AUTOSAR XML (schema 4-2-1)
package /RootP_ASWC_A27
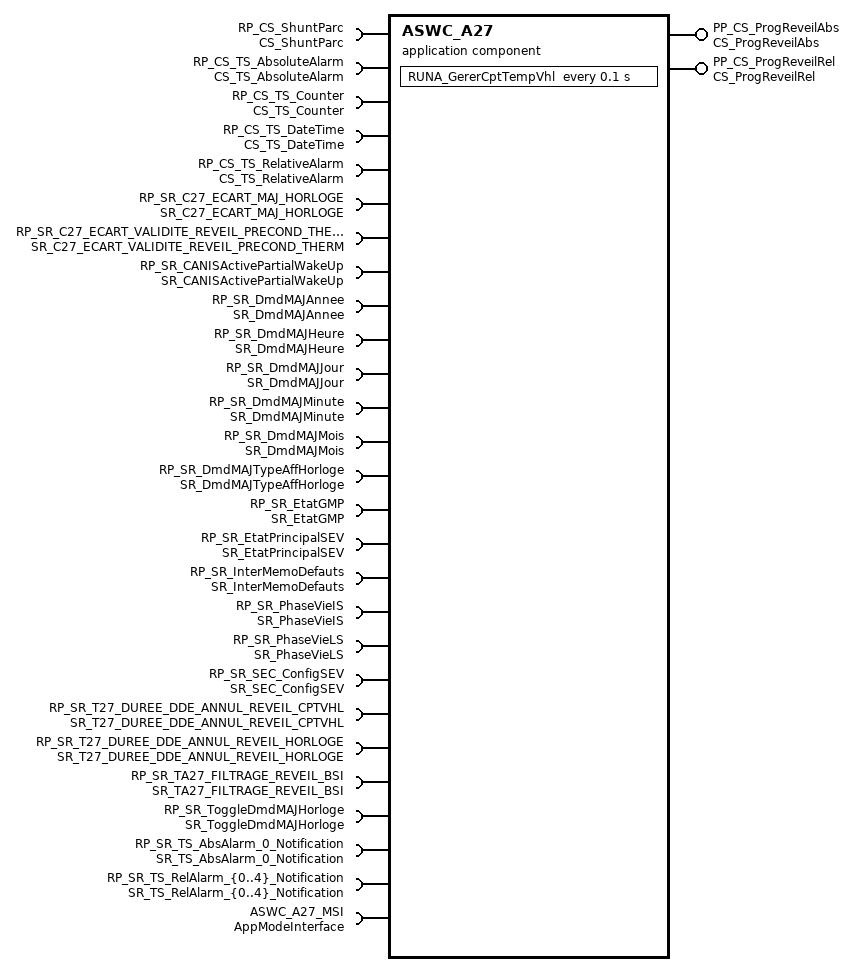
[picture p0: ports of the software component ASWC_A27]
  application sw component type ASWC_A27
    provide port PP_CS_ProgReveilAbs: provided-com-specs=[{operation=Release, queue-length=1}, {operation=Request, queue-length=1}], provided-interface=CS_ProgReveilAbs
    provide port PP_CS_ProgReveilRel: provided-com-specs=[{operation=Release, queue-length=1}, {operation=Request, queue-length=1}], provided-interface=CS_ProgReveilRel
    29 x provide/require port:
      PRP_SR_Annee: nonqueued-receiver-com-spec{data-element=Annee, enable-update=0, handle-data-status=1, handle-never-received=0, init-value=CONST_t_cAnnee_0x84E:2126}, provided-required-interface=SR_Annee
      PRP_SR_AnneePourAff: nonqueued-receiver-com-spec{data-element=AnneePourAff, enable-update=0, handle-data-status=1, handle-never-received=0, init-value=CONST_AnneePourAff_t_cAnneeAff_cAnneeAff_Indisponible:126}, provided-required-interface=SR_AnneePourAff
      PRP_SR_CptTempVehicule: nonqueued-receiver-com-spec{data-element=CptTempVehicule, enable-update=0, handle-data-status=1, handle-never-received=0, init-value=CONST_tDWORD_0xFFFFFFFE:4294967294}, provided-required-interface=SR_CptTempVehicule
      PRP_SR_DatationDefaut: nonqueued-receiver-com-spec{data-element=DatationDefaut, enable-update=0, handle-data-status=1, handle-never-received=0, init-value=CONST_tDWORD_0:0}, provided-required-interface=SR_DatationDefaut
      PRP_SR_Heure: nonqueued-receiver-com-spec{data-element=Heure, enable-update=0, handle-data-status=1, handle-never-received=0, init-value=CONST_Heure_t_cHeure_cHeure_Indisponible:30}, provided-required-interface=SR_Heure
      PRP_SR_HeureCAN: nonqueued-receiver-com-spec{data-element=HeureCAN, enable-update=0, handle-data-status=1, handle-never-received=0, init-value=CONST_HeureCAN_t_cHeure_cHeure_Indisponible:30}, provided-required-interface=SR_HeureCAN
      PRP_SR_Jour: nonqueued-receiver-com-spec{data-element=Jour, enable-update=0, handle-data-status=1, handle-never-received=0, init-value=CONST_t_cJour_0x3E:62}, provided-required-interface=SR_Jour
      PRP_SR_JourSemaine: nonqueued-receiver-com-spec{data-element=JourSemaine, enable-update=0, handle-data-status=1, handle-never-received=0, init-value=CONST_JourSemaine_t_cJourSemaine_cJourSemaine_Indisponible:14}, provided-required-interface=SR_JourSemaine
      PRP_SR_Minute: nonqueued-receiver-com-spec{data-element=Minute, enable-update=0, handle-data-status=1, handle-never-received=0, init-value=CONST_Minute_t_cMinute_cMinute_Indisponible:62}, provided-required-interface=SR_Minute
      PRP_SR_MinuteCAN: nonqueued-receiver-com-spec{data-element=MinuteCAN, enable-update=0, handle-data-status=1, handle-never-received=0, init-value=CONST_MinuteCAN_t_cMinute_cMinute_Indisponible:62}, provided-required-interface=SR_MinuteCAN
      PRP_SR_Mois: nonqueued-receiver-com-spec{data-element=Mois, enable-update=0, handle-data-status=1, handle-never-received=0, init-value=CONST_Mois_t_cMois_cMois_Indisponible:14}, provided-required-interface=SR_Mois
      PRP_SR_SEC_Affichage: nonqueued-receiver-com-spec{data-element=SEC_Affichage, enable-update=0, handle-data-status=1, handle-never-received=0, init-value=CONST_tLOG_1:1}, provided-required-interface=SR_SEC_Affichage
      PRP_SR_SEC_CptRAZGCT: nonqueued-receiver-com-spec{data-element=SEC_CptRAZGCT, enable-update=0, handle-data-status=1, handle-never-received=0, init-value=CONST_SEC_CptRAZGCT_t_cCptRAZ_cCptRAZ_Indisponible:254}, provided-required-interface=SR_SEC_CptRAZGCT
      PRP_SR_SEC_EtatProgRevGEEAQEB: nonqueued-receiver-com-spec{data-element=SEC_EtatProgRevGEEAQEB, enable-update=0, handle-data-status=1, handle-never-received=0, init-value=CONST_SEC_EtatProgRevGEEAQEB_t_cEtatProgRev_cEtatProgRev_ReveilNonProg:60}, provided-required-interface=SR_SEC_EtatProgRevGEEAQEB
      PRP_SR_SEC_EtatProgRevGEEDCM: nonqueued-receiver-com-spec{data-element=SEC_EtatProgRevGEEDCM, enable-update=0, handle-data-status=1, handle-never-received=0, init-value=CONST_SEC_EtatProgRevGEEDCM_t_cEtatProgRev_cEtatProgRev_ReveilNonProg:60}, provided-required-interface=SR_SEC_EtatProgRevGEEDCM
      PRP_SR_SEC_EtatProgRevPrecond: nonqueued-receiver-com-spec{data-element=SEC_EtatProgRevPrecond, enable-update=0, handle-data-status=1, handle-never-received=0, init-value=CONST_t_cEtatProgRev_0x96:150}, provided-required-interface=SR_SEC_EtatProgRevPrecond
      PRP_SR_SEC_EtatProgRevPrecondElec: nonqueued-receiver-com-spec{data-element=SEC_EtatProgRevPrecondElec, enable-update=0, handle-data-status=1, handle-never-received=0, init-value=CONST_tFLOAT_0x96:150}, provided-required-interface=SR_SEC_EtatProgRevPrecondElec
      PRP_SR_SEC_EtatProgRevPrecondTherm: nonqueued-receiver-com-spec{data-element=SEC_EtatProgRevPrecondTherm, enable-update=0, handle-data-status=1, handle-never-received=0, init-value=CONST_t_cEtatProgRev_0x96:150}, provided-required-interface=SR_SEC_EtatProgRevPrecondTherm
      PRP_SR_SEC_EtatProgRevRTAB: nonqueued-receiver-com-spec{data-element=SEC_EtatProgRevRTAB, enable-update=0, handle-data-status=1, handle-never-received=0, init-value=CONST_SEC_EtatProgRevRTAB_t_cEtatProgRev_cEtatProgRev_ReveilNonProg:60}, provided-required-interface=SR_SEC_EtatProgRevRTAB
      PRP_SR_SEC_HProgRevPrecondTherm: nonqueued-receiver-com-spec{data-element=SEC_HProgRevPrecondTherm, enable-update=0, handle-data-status=1, handle-never-received=0, init-value=CONST_SEC_HProgRevPrecondTherm_t_cHProgPrecondTherm_cHProgPrecondTherm_Aucun:65534}, provided-required-interface=SR_SEC_HProgRevPrecondTherm
      PRP_SR_SEC_TypeAffichageHorloge: nonqueued-receiver-com-spec{data-element=SEC_TypeAffichageHorloge, enable-update=0, handle-data-status=1, handle-never-received=0, init-value=CONST_SEC_TypeAffichageHorloge_t_cTypeAffichHor_cTypeAffichHor_24H:1}, provided-required-interface=SR_SEC_TypeAffichageHorloge
      PRP_SR_ToggleEnvCptTempVhl: nonqueued-receiver-com-spec{data-element=ToggleEnvCptTempVhl, enable-update=0, handle-data-status=1, handle-never-received=0, init-value=CONST_tLOG_0:0}, provided-required-interface=SR_ToggleEnvCptTempVhl
      PRP_SR_ToggleMAJDateHeure: nonqueued-receiver-com-spec{data-element=ToggleMAJDateHeure, enable-update=0, handle-data-status=1, handle-never-received=0, init-value=CONST_tLOG_0:0}, provided-required-interface=SR_ToggleMAJDateHeure
      PRP_SR_WSParTimerGEEAQEB: nonqueued-receiver-com-spec{data-element=WSParTimerGEEAQEB, enable-update=0, handle-data-status=1, handle-never-received=0, init-value=CONST_tLOG_0:0}, provided-required-interface=SR_WSParTimerGEEAQEB
      PRP_SR_WSParTimerGEEDCM: nonqueued-receiver-com-spec{data-element=WSParTimerGEEDCM, enable-update=0, handle-data-status=1, handle-never-received=0, init-value=CONST_tLOG_0:0}, provided-required-interface=SR_WSParTimerGEEDCM
      PRP_SR_WSParTimerPrecElec: nonqueued-receiver-com-spec{data-element=WSParTimerPrecElec, enable-update=0, handle-data-status=1, handle-never-received=0, init-value=CONST_tLOG_0:0}, provided-required-interface=SR_WSParTimerPrecElec
      PRP_SR_WSParTimerPrecond: nonqueued-receiver-com-spec{data-element=WSParTimerPrecond, enable-update=0, handle-data-status=1, handle-never-received=0, init-value=CONST_tLOG_0:0}, provided-required-interface=SR_WSParTimerPrecond
      PRP_SR_WSParTimerPrecTherm: nonqueued-receiver-com-spec{data-element=WSParTimerPrecTherm, enable-update=0, handle-data-status=1, handle-never-received=0, init-value=CONST_tLOG_0:0}, provided-required-interface=SR_WSParTimerPrecTherm
      PRP_SR_WSParTimerRTAB: nonqueued-receiver-com-spec{data-element=WSParTimerRTAB, enable-update=0, handle-data-status=1, handle-never-received=0, init-value=CONST_tLOG_0:0}, provided-required-interface=SR_WSParTimerRTAB
    31 x require port:
      RP_CS_ShuntParc: required-interface=CS_ShuntParc
      RP_CS_TS_AbsoluteAlarm: required-interface=CS_TS_AbsoluteAlarm
      RP_CS_TS_Counter: required-interface=CS_TS_Counter
      RP_CS_TS_DateTime: required-interface=CS_TS_DateTime
      RP_CS_TS_RelativeAlarm: required-interface=CS_TS_RelativeAlarm
      RP_SR_C27_ECART_MAJ_HORLOGE: nonqueued-receiver-com-spec{data-element=C27_ECART_MAJ_HORLOGE, enable-update=0, handle-data-status=1, handle-never-received=0, init-value=CONST_t_C27_ECART_MAJ_HORLOGE_60:60}, required-interface=SR_C27_ECART_MAJ_HORLOGE
      RP_SR_C27_ECART_VALIDITE_REVEIL_PRECOND_THERM: nonqueued-receiver-com-spec{data-element=C27_ECART_VALIDITE_REVEIL_PRECOND_THERM, enable-update=0, handle-data-status=1, handle-never-received=0, init-value=CONST_tBYTE_60:60}, required-interface=SR_C27_ECART_VALIDITE_REVEIL_PRECOND_THERM
      RP_SR_CANISActivePartialWakeUp: nonqueued-receiver-com-spec{data-element=CANISActivePartialWakeUp, enable-update=0, handle-data-status=1, handle-never-received=0, init-value=CONST_t_cCANISPartialWakeUp_0:0}, required-interface=SR_CANISActivePartialWakeUp
      RP_SR_DmdMAJAnnee: nonqueued-receiver-com-spec{data-element=DmdMAJAnnee, enable-update=0, handle-data-status=1, handle-never-received=0, init-value=CONST_DmdMAJAnnee_t_cAnnee_cAnnee_Indisponible:2126}, required-interface=SR_DmdMAJAnnee
      RP_SR_DmdMAJHeure: nonqueued-receiver-com-spec{data-element=DmdMAJHeure, enable-update=0, handle-data-status=1, handle-never-received=0, init-value=CONST_DmdMAJHeure_t_cHeure_cHeure_Indisponible:30}, required-interface=SR_DmdMAJHeure
      RP_SR_DmdMAJJour: nonqueued-receiver-com-spec{data-element=DmdMAJJour, enable-update=0, handle-data-status=1, handle-never-received=0, init-value=CONST_DmdMAJJour_t_cJour_cJour_Indisponible:62}, required-interface=SR_DmdMAJJour
      RP_SR_DmdMAJMinute: nonqueued-receiver-com-spec{data-element=DmdMAJMinute, enable-update=0, handle-data-status=1, handle-never-received=0, init-value=CONST_DmdMAJMinute_t_cMinute_cMinute_Indisponible:62}, required-interface=SR_DmdMAJMinute
      RP_SR_DmdMAJMois: nonqueued-receiver-com-spec{data-element=DmdMAJMois, enable-update=0, handle-data-status=1, handle-never-received=0, init-value=CONST_DmdMAJMois_t_cMois_cMois_Indisponible:14}, required-interface=SR_DmdMAJMois
      RP_SR_DmdMAJTypeAffHorloge: nonqueued-receiver-com-spec{data-element=DmdMAJTypeAffHorloge, enable-update=0, handle-data-status=1, handle-never-received=0, init-value=CONST_DmdMAJTypeAffHorloge_t_cTypeAffichHor_cTypeAffichHor_24H:1}, required-interface=SR_DmdMAJTypeAffHorloge
      RP_SR_EtatGMP: nonqueued-receiver-com-spec{data-element=EtatGMP, enable-update=0, handle-data-status=1, handle-never-received=0, init-value=CONST_t_GM_GMP_1:1}, required-interface=SR_EtatGMP
      RP_SR_EtatPrincipalSEV: nonqueued-receiver-com-spec{data-element=EtatPrincipalSEV, enable-update=0, handle-data-status=1, handle-never-received=0, init-value=CONST_t_SEV_0x69:105}, required-interface=SR_EtatPrincipalSEV
      RP_SR_InterMemoDefauts: nonqueued-receiver-com-spec{data-element=InterMemoDefauts, enable-update=0, handle-data-status=1, handle-never-received=0, init-value=CONST_tLOG_0:0}, required-interface=SR_InterMemoDefauts
      RP_SR_PhaseVieIS: nonqueued-receiver-com-spec{data-element=PhaseVieIS, enable-update=0, handle-data-status=1, handle-never-received=0, init-value=CONST_PhaseVieIS_t_cCANIS_cCANIS_OFF:0}, required-interface=SR_PhaseVieIS
      RP_SR_PhaseVieLS: nonqueued-receiver-com-spec{data-element=PhaseVieLS, enable-update=0, handle-data-status=1, handle-never-received=0, init-value=CONST_t_cCANLS_0:0}, required-interface=SR_PhaseVieLS
      RP_SR_SEC_ConfigSEV: nonqueued-receiver-com-spec{data-element=SEC_ConfigSEV, enable-update=0, handle-data-status=1, handle-never-received=0, init-value=CONST_t_cCSEV_4:4}, required-interface=SR_SEC_ConfigSEV
      RP_SR_T27_DUREE_DDE_ANNUL_REVEIL_CPTVHL: nonqueued-receiver-com-spec{data-element=T27_DUREE_DDE_ANNUL_REVEIL_CPTVHL, enable-update=0, handle-data-status=1, handle-never-received=0, init-value=CONST_tBYTE_20:20}, required-interface=SR_T27_DUREE_DDE_ANNUL_REVEIL_CPTVHL
      RP_SR_T27_DUREE_DDE_ANNUL_REVEIL_HORLOGE: nonqueued-receiver-com-spec{data-element=T27_DUREE_DDE_ANNUL_REVEIL_HORLOGE, enable-update=0, handle-data-status=1, handle-never-received=0, init-value=CONST_tBYTE_20:20}, required-interface=SR_T27_DUREE_DDE_ANNUL_REVEIL_HORLOGE
      RP_SR_TA27_FILTRAGE_REVEIL_BSI: nonqueued-receiver-com-spec{data-element=TA27_FILTRAGE_REVEIL_BSI, enable-update=0, handle-data-status=1, handle-never-received=0, init-value=CONST_tBYTE_2:2}, required-interface=SR_TA27_FILTRAGE_REVEIL_BSI
      RP_SR_ToggleDmdMAJHorloge: nonqueued-receiver-com-spec{data-element=ToggleDmdMAJHorloge, enable-update=0, handle-data-status=1, handle-never-received=0, init-value=CONST_tLOG_0:0}, required-interface=SR_ToggleDmdMAJHorloge
      RP_SR_TS_AbsAlarm_0_Notification: nonqueued-receiver-com-spec{data-element=AbsAlarm_0_State, enable-update=0, handle-data-status=1, handle-never-received=0, init-value=CONST_t_cAlarm_0:0}, required-interface=SR_TS_AbsAlarm_0_Notification
      RP_SR_TS_RelAlarm_{0..4}_Notification: nonqueued-receiver-com-spec{data-element=RelAlarm_{0..4}_State, enable-update=0, handle-data-status=1, handle-never-received=0, init-value=CONST_t_cAlarm_0:0}, required-interface=SR_TS_RelAlarm_{0..4}_Notification
      ASWC_A27_MSI: required-interface=AppModeInterface
    behavior IB_ASWC_A27: data-type-mapping=ApplicationModeMapping, handle-termination-and-restart=NO-SUPPORT
      ar-typed-per-instance-memorys:
        45 x data:
          PA27_AnneePrec: type=t_cAnnee, init-value=CONST_PA27_AnneePrec_t_cAnnee_cAnnee_Indisponible:2126
          PA27_CoherenceDate_NOK: type=tLOG, init-value=CONST_tLOG_0:0
          PA27_ConditionsMAJDateHeureOK: type=tLOG, init-value=CONST_tLOG_0:0
          PA27_ConditionsRtMAJCptTempVhlOK: type=tLOG, init-value=CONST_tLOG_0:0
          PA27_CptTempoAppa_ABS_SAVE_CPT_TEMPOREL: type=tWORD, init-value=CONST_tWORD_0:0
          PA27_CptTempoAppa_HorlogeInvalide: type=tWORD, init-value=CONST_tWORD_0:0
          PA27_CptTempoDisp_ABS_SAVE_CPT_TEMPOREL: type=tWORD, init-value=CONST_tWORD_0:0
          PA27_CptTempoDisp_HorlogeInvalide: type=tWORD, init-value=CONST_tWORD_0:0
          PA27_DateTimeInv: type=tLOG, init-value=CONST_tLOG_0:0
          PA27_DbrtBATT_Prec: type=tLOG, init-value=CONST_tLOG_0:0
          PA27_DefautPrec_ABS_SAVE_CPT_TEMPOREL: type=tBYTE, init-value=CONST_tBYTE_0:0
          PA27_DefautPrec_HorlogeInvalide: type=tBYTE, init-value=CONST_tBYTE_0:0
          PA27_EntreesRtMAJDateHeureOK: type=tLOG, init-value=CONST_tLOG_0:0
          PA27_EnvCptTempVhl: type=tLOG, init-value=CONST_tLOG_0:0
          PA27_Flag_DEF_ABS_SAVE_CPT_TEMPOREL: type=tLOG, init-value=CONST_tLOG_0:0
          PA27_FlagDeRtDde_MAJDateHeure: type=tBinaire, init-value=CONST_PA27_FlagDeRtDde_MAJDateHeure_tBinaire_cFaux:0
          PA27_FlagDeRtMAJCptTempVhlOK: type=tBinaire, init-value=CONST_PA27_FlagDeRtMAJCptTempVhlOK_tBinaire_cFaux:0
          PA27_HeurePrec: type=t_cHeure, init-value=CONST_PA27_HeurePrec_t_cHeure_cHeure_Indisponible:30
          PA27_HeurePREC: type=t_cHeure, init-value=CONST_PA27_HeurePREC_t_cHeure_cHeure_Indisponible:30
          PA27_InvPrecTimeEnMinute: type=tLOG, init-value=CONST_tLOG_0:0
          PA27_JourPrec: type=t_cJour, init-value=CONST_PA27_JourPrec_t_cJour_cJour_Indisponible:62
          PA27_MajCptTempViaRequeteMAJ: type=tLOG, init-value=CONST_tLOG_0:0
          PA27_MAJDateHeure: type=tLOG, init-value=CONST_tLOG_0:0
          PA27_MajDateHeureViaRequeteMAJ: type=tLOG, init-value=CONST_tLOG_0:0
          PA27_MinutePrec: type=t_cMinute, init-value=CONST_PA27_MinutePrec_t_cMinute_cMinute_Indisponible:62
          PA27_MoisPrec: type=t_cMois, init-value=CONST_PA27_MoisPrec_t_cMois_cMois_Indisponible:14
          PA27_NbToggEnvCptTempVhl: type=tBYTE, init-value=CONST_tBYTE_0:0
          PA27_OldCANISActPartWU: type=tDWORD, init-value=CONST_tDWORD_0:0
          PA27_OldMAJCptTempVhl: type=tLOG, init-value=CONST_tLOG_0:0
          PA27_OldMAJDateHeure: type=tLOG, init-value=CONST_tLOG_0:0
          PA27_OldPhaseVieIS: type=t_cCANIS, init-value=CONST_PA27_OldPhaseVieIS_t_cCANIS_cCANIS_OFF:0
          PA27_OldRAZReveilHorloge: type=tLOG, init-value=CONST_tLOG_0:0
          PA27_OldRAZReveilProgramme: type=tLOG, init-value=CONST_tLOG_0:0
          PA27_OldStateDef2_ABS_SAVE_CPT_TEMPOREL: type=tBYTE, init-value=CONST_tBYTE_0:0
          PA27_OldStateDef2_HorlogeInvalide: type=tBYTE, init-value=CONST_tBYTE_0:0
          PA27_PhaseVieLSPrec_ABS_SAVE_CPT_TEMPOREL: type=t_cCANLS, init-value=CONST_PA27_PhaseVieLSPrec_ABS_SAVE_CPT_TEMPOREL_t_cCANLS_cCANLS_VEILLE:0
          PA27_PhaseVieLSPrec_HorlogeInvalide: type=t_cCANLS, init-value=CONST_PA27_PhaseVieLSPrec_HorlogeInvalide_t_cCANLS_cCANLS_VEILLE:0
          PA27_RAZReveilHorloge: type=tLOG, init-value=CONST_tLOG_0:0
          PA27_RAZReveilProgramme: type=tLOG, init-value=CONST_tLOG_0:0
          PA27_ResetBSI: type=tLOG, init-value=CONST_tLOG_1:1
          PA27_TempoDdeRAZReveil: type=tBYTE, init-value=CONST_tBYTE_0:0
          PA27_TempoDeFiltrage_Reveil_BSI: type=tBYTE, init-value=CONST_tBYTE_0:0
          PA27_TempoRAZReveilHorloge: type=tBYTE, init-value=CONST_tBYTE_0:0
          PA27_TimeEnMinute: type=tWORD, init-value=CONST_tWORD_0:0
          PA27_ToggleDmdMAJHorloge_Prec: type=tLOG, init-value=CONST_tLOG_0:0
      4 x operation invoked event:
        CS_ProgReveilAbs_Release_OIE: start-on-event=RUNS_ProgReveilAbs_Release, operation=PP_CS_ProgReveilAbs.Release
        CS_ProgReveilAbs_Request_OIE: start-on-event=RUNS_ProgReveilAbs_Request, operation=PP_CS_ProgReveilAbs.Request
        CS_ProgReveilRel_Release_OIE: start-on-event=RUNS_ProgReveilRel_Release, operation=PP_CS_ProgReveilRel.Release
        CS_ProgReveilRel_Request_OIE: start-on-event=RUNS_ProgReveilRel_Request, operation=PP_CS_ProgReveilRel.Request
      timing event RUNA_GererCptTempVhl_Cyclic: start-on-event=RUNA_GererCptTempVhl, period=0.1
        disabled-mode:
          ASWC_A27_MSI.AppMode.APP_WAKEUP
          ASWC_A27_MSI.AppMode.APP_OFF
          ASWC_A27_MSI.AppMode.APP_SYNC_INIT
          ASWC_A27_MSI.AppMode.APP_CONFIG
      swc mode switch event RUNPI_ASWC_A27_ENTRY: start-on-event=RUNPI_ASWC_A27, activation=ON-ENTRY, mode=ASWC_A27_MSI.AppMode.APP_WAKEUP
      swc mode switch event RUNI_A27_EXIT: start-on-event=RUNI_A27, activation=ON-EXIT, mode=ASWC_A27_MSI.AppMode.APP_WAKEUP
      implicit-inter-runnable-variables:
        19 x data:
          IRVA27_DbrtBATT: type=tLOG, init-value=CONST_tLOG_0:0
          IRVA27_DeProg_AbsAlarm_All: type=tLOG, init-value=CONST_tLOG_0:0
          IRVA27_DeProg_AbsAlarm_PreCond: type=tLOG, init-value=CONST_tLOG_0:0
          IRVA27_DeProg_AbsAlarm_PT: type=tLOG, init-value=CONST_tLOG_0:0
          IRVA27_DeProg_RelAlarm_All: type=tLOG, init-value=CONST_tLOG_0:0
          IRVA27_DeProg_RelAlarm_AQEB: type=tLOG, init-value=CONST_tLOG_0:0
          IRVA27_DeProg_RelAlarm_DCM: type=tLOG, init-value=CONST_tLOG_0:0
          IRVA27_DeProg_RelAlarm_PE: type=tLOG, init-value=CONST_tLOG_0:0
          IRVA27_DeProg_RelAlarm_PreCond: type=tLOG, init-value=CONST_tLOG_0:0
          IRVA27_DeProg_RelAlarm_RTAB: type=tLOG, init-value=CONST_tLOG_0:0
          IRVA27_OldTimeEnMinute: type=tWORD, init-value=CONST_tWORD_0:0
          IRVA27_ReveilBSI: type=tLOG, init-value=CONST_tLOG_0:0
          IRVA27_SAV_OldCptTempVehicule: type=t_cCptVhl, init-value=CONST_IRVA27_SAV_OldCptTempVehicule_t_cCptVhl_cCptVhl_Indisponible:4294967294
          IRVA27_SEC_TchgtBSIDbrtBATT: type=tLOG, init-value=CONST_tLOG_0:0
          IRVA27_SEC_TProgReveilGEEAQEB: type=tDWORD, init-value=CONST_tDWORD_0:0
          IRVA27_SEC_TProgReveilGEEDCM: type=tDWORD, init-value=CONST_tDWORD_0:0
          IRVA27_SEC_TProgReveilPE: type=tDWORD, init-value=CONST_tDWORD_0:0
          IRVA27_SEC_TProgReveilPreCond: type=tDWORD, init-value=CONST_tDWORD_0:0
          IRVA27_SEC_TProgReveilRTAB: type=tDWORD, init-value=CONST_tDWORD_0:0
      7 x runnable:
        RUNA_GererCptTempVhl
          data-read-access:
            48 x access:
              dra_WSParTimerGEEAQEB: accessed-variable=PRP_SR_WSParTimerGEEAQEB.WSParTimerGEEAQEB
              dra_WSParTimerGEEDCM: accessed-variable=PRP_SR_WSParTimerGEEDCM.WSParTimerGEEDCM
              dra_WSParTimerPrecElec: accessed-variable=PRP_SR_WSParTimerPrecElec.WSParTimerPrecElec
              dra_WSParTimerPrecond: accessed-variable=PRP_SR_WSParTimerPrecond.WSParTimerPrecond
              dra_WSParTimerPrecTherm: accessed-variable=PRP_SR_WSParTimerPrecTherm.WSParTimerPrecTherm
              dra_WSParTimerRTAB: accessed-variable=PRP_SR_WSParTimerRTAB.WSParTimerRTAB
              dra_CANISActivePartialWakeUp: accessed-variable=RP_SR_CANISActivePartialWakeUp.CANISActivePartialWakeUp
              dra_DmdMAJAnnee: accessed-variable=RP_SR_DmdMAJAnnee.DmdMAJAnnee
              dra_DmdMAJHeure: accessed-variable=RP_SR_DmdMAJHeure.DmdMAJHeure
              dra_DmdMAJJour: accessed-variable=RP_SR_DmdMAJJour.DmdMAJJour
              dra_DmdMAJMinute: accessed-variable=RP_SR_DmdMAJMinute.DmdMAJMinute
              dra_DmdMAJMois: accessed-variable=RP_SR_DmdMAJMois.DmdMAJMois
              dra_DmdMAJTypeAffHorloge: accessed-variable=RP_SR_DmdMAJTypeAffHorloge.DmdMAJTypeAffHorloge
              dra_EtatGMP: accessed-variable=RP_SR_EtatGMP.EtatGMP
              dra_EtatPrincipalSEV: accessed-variable=RP_SR_EtatPrincipalSEV.EtatPrincipalSEV
              dra_InterMemoDefauts: accessed-variable=RP_SR_InterMemoDefauts.InterMemoDefauts
              dra_PhaseVieIS: accessed-variable=RP_SR_PhaseVieIS.PhaseVieIS
              dra_PhaseVieLS: accessed-variable=RP_SR_PhaseVieLS.PhaseVieLS
              dra_SEC_ConfigSEV: accessed-variable=RP_SR_SEC_ConfigSEV.SEC_ConfigSEV
              dra_ToggleDmdMAJHorloge: accessed-variable=RP_SR_ToggleDmdMAJHorloge.ToggleDmdMAJHorloge
              dra_C27_ECART_MAJ_HORLOGE: accessed-variable=RP_SR_C27_ECART_MAJ_HORLOGE.C27_ECART_MAJ_HORLOGE
              dra_C27_ECART_VALIDITE_REVEIL_PRECOND_THERM: accessed-variable=RP_SR_C27_ECART_VALIDITE_REVEIL_PRECOND_THERM.C27_ECART_VALIDITE_REVEIL_PRECOND_THERM
              dra_T27_DUREE_DDE_ANNUL_REVEIL_CPTVHL: accessed-variable=RP_SR_T27_DUREE_DDE_ANNUL_REVEIL_CPTVHL.T27_DUREE_DDE_ANNUL_REVEIL_CPTVHL
              dra_T27_DUREE_DDE_ANNUL_REVEIL_HORLOGE: accessed-variable=RP_SR_T27_DUREE_DDE_ANNUL_REVEIL_HORLOGE.T27_DUREE_DDE_ANNUL_REVEIL_HORLOGE
              dra_TA27_FILTRAGE_REVEIL_BSI: accessed-variable=RP_SR_TA27_FILTRAGE_REVEIL_BSI.TA27_FILTRAGE_REVEIL_BSI
              dra_Annee: accessed-variable=PRP_SR_Annee.Annee
              dra_AnneePourAff: accessed-variable=PRP_SR_AnneePourAff.AnneePourAff
              dra_CptTempVehicule: accessed-variable=PRP_SR_CptTempVehicule.CptTempVehicule
              dra_DatationDefaut: accessed-variable=PRP_SR_DatationDefaut.DatationDefaut
              dra_Heure: accessed-variable=PRP_SR_Heure.Heure
              dra_HeureCAN: accessed-variable=PRP_SR_HeureCAN.HeureCAN
              dra_Jour: accessed-variable=PRP_SR_Jour.Jour
              dra_JourSemaine: accessed-variable=PRP_SR_JourSemaine.JourSemaine
              dra_Minute: accessed-variable=PRP_SR_Minute.Minute
              dra_MinuteCAN: accessed-variable=PRP_SR_MinuteCAN.MinuteCAN
              dra_Mois: accessed-variable=PRP_SR_Mois.Mois
              dra_SEC_Affichage: accessed-variable=PRP_SR_SEC_Affichage.SEC_Affichage
              dra_SEC_CptRAZGCT: accessed-variable=PRP_SR_SEC_CptRAZGCT.SEC_CptRAZGCT
              dra_SEC_EtatProgRevGEEAQEB: accessed-variable=PRP_SR_SEC_EtatProgRevGEEAQEB.SEC_EtatProgRevGEEAQEB
              dra_SEC_EtatProgRevGEEDCM: accessed-variable=PRP_SR_SEC_EtatProgRevGEEDCM.SEC_EtatProgRevGEEDCM
              dra_SEC_EtatProgRevPrecond: accessed-variable=PRP_SR_SEC_EtatProgRevPrecond.SEC_EtatProgRevPrecond
              dra_SEC_EtatProgRevPrecondElec: accessed-variable=PRP_SR_SEC_EtatProgRevPrecondElec.SEC_EtatProgRevPrecondElec
              dra_SEC_EtatProgRevPrecondTherm: accessed-variable=PRP_SR_SEC_EtatProgRevPrecondTherm.SEC_EtatProgRevPrecondTherm
              dra_SEC_EtatProgRevRTAB: accessed-variable=PRP_SR_SEC_EtatProgRevRTAB.SEC_EtatProgRevRTAB
              dra_SEC_HProgRevPrecondTherm: accessed-variable=PRP_SR_SEC_HProgRevPrecondTherm.SEC_HProgRevPrecondTherm
              dra_SEC_TypeAffichageHorloge: accessed-variable=PRP_SR_SEC_TypeAffichageHorloge.SEC_TypeAffichageHorloge
              dra_ToggleEnvCptTempVhl: accessed-variable=PRP_SR_ToggleEnvCptTempVhl.ToggleEnvCptTempVhl
              dra_ToggleMAJDateHeure: accessed-variable=PRP_SR_ToggleMAJDateHeure.ToggleMAJDateHeure
          data-write-access:
            23 x access:
              dwa_Annee: accessed-variable=PRP_SR_Annee.Annee
              dwa_AnneePourAff: accessed-variable=PRP_SR_AnneePourAff.AnneePourAff
              dwa_CptTempVehicule: accessed-variable=PRP_SR_CptTempVehicule.CptTempVehicule
              dwa_DatationDefaut: accessed-variable=PRP_SR_DatationDefaut.DatationDefaut
              dwa_Heure: accessed-variable=PRP_SR_Heure.Heure
              dwa_HeureCAN: accessed-variable=PRP_SR_HeureCAN.HeureCAN
              dwa_Jour: accessed-variable=PRP_SR_Jour.Jour
              dwa_JourSemaine: accessed-variable=PRP_SR_JourSemaine.JourSemaine
              dwa_Minute: accessed-variable=PRP_SR_Minute.Minute
              dwa_MinuteCAN: accessed-variable=PRP_SR_MinuteCAN.MinuteCAN
              dwa_Mois: accessed-variable=PRP_SR_Mois.Mois
              dwa_SEC_Affichage: accessed-variable=PRP_SR_SEC_Affichage.SEC_Affichage
              dwa_SEC_CptRAZGCT: accessed-variable=PRP_SR_SEC_CptRAZGCT.SEC_CptRAZGCT
              dwa_SEC_EtatProgRevGEEAQEB: accessed-variable=PRP_SR_SEC_EtatProgRevGEEAQEB.SEC_EtatProgRevGEEAQEB
              dwa_SEC_EtatProgRevGEEDCM: accessed-variable=PRP_SR_SEC_EtatProgRevGEEDCM.SEC_EtatProgRevGEEDCM
              dwa_SEC_EtatProgRevPrecond: accessed-variable=PRP_SR_SEC_EtatProgRevPrecond.SEC_EtatProgRevPrecond
              dwa_SEC_EtatProgRevPrecondElec: accessed-variable=PRP_SR_SEC_EtatProgRevPrecondElec.SEC_EtatProgRevPrecondElec
              dwa_SEC_EtatProgRevPrecondTherm: accessed-variable=PRP_SR_SEC_EtatProgRevPrecondTherm.SEC_EtatProgRevPrecondTherm
              dwa_SEC_EtatProgRevRTAB: accessed-variable=PRP_SR_SEC_EtatProgRevRTAB.SEC_EtatProgRevRTAB
              dwa_SEC_HProgRevPrecondTherm: accessed-variable=PRP_SR_SEC_HProgRevPrecondTherm.SEC_HProgRevPrecondTherm
              dwa_SEC_TypeAffichageHorloge: accessed-variable=PRP_SR_SEC_TypeAffichageHorloge.SEC_TypeAffichageHorloge
              dwa_ToggleEnvCptTempVhl: accessed-variable=PRP_SR_ToggleEnvCptTempVhl.ToggleEnvCptTempVhl
              dwa_ToggleMAJDateHeure: accessed-variable=PRP_SR_ToggleMAJDateHeure.ToggleMAJDateHeure
          read-local-variables:
            19 x access:
              rlv_IRVA27_DbrtBATT: accessed-variable=IRVA27_DbrtBATT
              rlv_IRVA27_DeProg_AbsAlarm_All: accessed-variable=IRVA27_DeProg_AbsAlarm_All
              rlv_IRVA27_DeProg_AbsAlarm_PreCond: accessed-variable=IRVA27_DeProg_AbsAlarm_PreCond
              rlv_IRVA27_DeProg_AbsAlarm_PT: accessed-variable=IRVA27_DeProg_AbsAlarm_PT
              rlv_IRVA27_DeProg_RelAlarm_All: accessed-variable=IRVA27_DeProg_RelAlarm_All
              rlv_IRVA27_DeProg_RelAlarm_AQEB: accessed-variable=IRVA27_DeProg_RelAlarm_AQEB
              rlv_IRVA27_DeProg_RelAlarm_DCM: accessed-variable=IRVA27_DeProg_RelAlarm_DCM
              rlv_IRVA27_DeProg_RelAlarm_PE: accessed-variable=IRVA27_DeProg_RelAlarm_PE
              rlv_IRVA27_DeProg_RelAlarm_PreCond: accessed-variable=IRVA27_DeProg_RelAlarm_PreCond
              rlv_IRVA27_DeProg_RelAlarm_RTAB: accessed-variable=IRVA27_DeProg_RelAlarm_RTAB
              rlv_IRVA27_OldTimeEnMinute: accessed-variable=IRVA27_OldTimeEnMinute
              rlv_IRVA27_ReveilBSI: accessed-variable=IRVA27_ReveilBSI
              rlv_IRVA27_SAV_OldCptTempVehicule: accessed-variable=IRVA27_SAV_OldCptTempVehicule
              rlv_IRVA27_SEC_TchgtBSIDbrtBATT: accessed-variable=IRVA27_SEC_TchgtBSIDbrtBATT
              rlv_IRVA27_SEC_TProgReveilGEEAQEB: accessed-variable=IRVA27_SEC_TProgReveilGEEAQEB
              rlv_IRVA27_SEC_TProgReveilGEEDCM: accessed-variable=IRVA27_SEC_TProgReveilGEEDCM
              rlv_IRVA27_SEC_TProgReveilPE: accessed-variable=IRVA27_SEC_TProgReveilPE
              rlv_IRVA27_SEC_TProgReveilPreCond: accessed-variable=IRVA27_SEC_TProgReveilPreCond
              rlv_IRVA27_SEC_TProgReveilRTAB: accessed-variable=IRVA27_SEC_TProgReveilRTAB
          11 x sync call, all with timeout=0:
            sscp_RUNA_GererCptTempVhl_CS_TS_AbsoluteAlarm_AbsAlarm_Clear: operation=RP_CS_TS_AbsoluteAlarm.AbsAlarm_Clear
            sscp_RUNA_GererCptTempVhl_CS_TS_AbsoluteAlarm_AbsAlarm_ClearAll: operation=RP_CS_TS_AbsoluteAlarm.AbsAlarm_ClearAll
            sscp_RUNA_GererCptTempVhl_CS_TS_Counter_Cnt_Get: operation=RP_CS_TS_Counter.Cnt_Get
            sscp_RUNA_GererCptTempVhl_CS_TS_Counter_Cnt_Set: operation=RP_CS_TS_Counter.Cnt_Set
            sscp_RUNA_GererCptTempVhl_CS_TS_DateTime_Date_Get: operation=RP_CS_TS_DateTime.Date_Get
            sscp_RUNA_GererCptTempVhl_CS_TS_DateTime_Date_Set: operation=RP_CS_TS_DateTime.Date_Set
            sscp_RUNA_GererCptTempVhl_CS_ShuntParc_OP_GET: operation=RP_CS_ShuntParc.OP_GET
            sscp_RUNA_GererCptTempVhl_CS_TS_RelativeAlarm_RelAlarm_Clear: operation=RP_CS_TS_RelativeAlarm.RelAlarm_Clear
            sscp_RUNA_GererCptTempVhl_CS_TS_RelativeAlarm_RelAlarm_ClearAll: operation=RP_CS_TS_RelativeAlarm.RelAlarm_ClearAll
            sscp_RUNA_GererCptTempVhl_CS_TS_DateTime_Time_Get: operation=RP_CS_TS_DateTime.Time_Get
            sscp_RUNA_GererCptTempVhl_CS_TS_DateTime_Time_Set: operation=RP_CS_TS_DateTime.Time_Set
          written-local-variables:
            12 x access:
              wlv_IRVA27_DeProg_AbsAlarm_All: accessed-variable=IRVA27_DeProg_AbsAlarm_All
              wlv_IRVA27_DeProg_AbsAlarm_PreCond: accessed-variable=IRVA27_DeProg_AbsAlarm_PreCond
              wlv_IRVA27_DeProg_AbsAlarm_PT: accessed-variable=IRVA27_DeProg_AbsAlarm_PT
              wlv_IRVA27_DeProg_RelAlarm_All: accessed-variable=IRVA27_DeProg_RelAlarm_All
              wlv_IRVA27_DeProg_RelAlarm_AQEB: accessed-variable=IRVA27_DeProg_RelAlarm_AQEB
              wlv_IRVA27_DeProg_RelAlarm_DCM: accessed-variable=IRVA27_DeProg_RelAlarm_DCM
              wlv_IRVA27_DeProg_RelAlarm_PE: accessed-variable=IRVA27_DeProg_RelAlarm_PE
              wlv_IRVA27_DeProg_RelAlarm_PreCond: accessed-variable=IRVA27_DeProg_RelAlarm_PreCond
              wlv_IRVA27_DeProg_RelAlarm_RTAB: accessed-variable=IRVA27_DeProg_RelAlarm_RTAB
              wlv_IRVA27_OldTimeEnMinute: accessed-variable=IRVA27_OldTimeEnMinute
              wlv_IRVA27_ReveilBSI: accessed-variable=IRVA27_ReveilBSI
              wlv_IRVA27_SAV_OldCptTempVehicule: accessed-variable=IRVA27_SAV_OldCptTempVehicule
        RUNI_A27
          data-read-access:
            30 x access:
              dra_AbsAlarm_0_State: accessed-variable=RP_SR_TS_AbsAlarm_0_Notification.AbsAlarm_0_State
              dra_RelAlarm_{0..4}_State: accessed-variable=RP_SR_TS_RelAlarm_{0..4}_Notification.RelAlarm_{0..4}_State
              dra_SEC_ConfigSEV: accessed-variable=RP_SR_SEC_ConfigSEV.SEC_ConfigSEV
              dra_Annee: accessed-variable=PRP_SR_Annee.Annee
              dra_AnneePourAff: accessed-variable=PRP_SR_AnneePourAff.AnneePourAff
              dra_CptTempVehicule: accessed-variable=PRP_SR_CptTempVehicule.CptTempVehicule
              dra_Heure: accessed-variable=PRP_SR_Heure.Heure
              dra_HeureCAN: accessed-variable=PRP_SR_HeureCAN.HeureCAN
              dra_Jour: accessed-variable=PRP_SR_Jour.Jour
              dra_Minute: accessed-variable=PRP_SR_Minute.Minute
              dra_MinuteCAN: accessed-variable=PRP_SR_MinuteCAN.MinuteCAN
              dra_Mois: accessed-variable=PRP_SR_Mois.Mois
              dra_SEC_Affichage: accessed-variable=PRP_SR_SEC_Affichage.SEC_Affichage
              dra_SEC_EtatProgRevGEEAQEB: accessed-variable=PRP_SR_SEC_EtatProgRevGEEAQEB.SEC_EtatProgRevGEEAQEB
              dra_SEC_EtatProgRevGEEDCM: accessed-variable=PRP_SR_SEC_EtatProgRevGEEDCM.SEC_EtatProgRevGEEDCM
              dra_SEC_EtatProgRevPrecondElec: accessed-variable=PRP_SR_SEC_EtatProgRevPrecondElec.SEC_EtatProgRevPrecondElec
              dra_SEC_EtatProgRevPrecondTherm: accessed-variable=PRP_SR_SEC_EtatProgRevPrecondTherm.SEC_EtatProgRevPrecondTherm
              dra_SEC_EtatProgRevRTAB: accessed-variable=PRP_SR_SEC_EtatProgRevRTAB.SEC_EtatProgRevRTAB
              dra_SEC_HProgRevPrecondTherm: accessed-variable=PRP_SR_SEC_HProgRevPrecondTherm.SEC_HProgRevPrecondTherm
              dra_SEC_TypeAffichageHorloge: accessed-variable=PRP_SR_SEC_TypeAffichageHorloge.SEC_TypeAffichageHorloge
              dra_WSParTimerGEEAQEB: accessed-variable=PRP_SR_WSParTimerGEEAQEB.WSParTimerGEEAQEB
              dra_WSParTimerGEEDCM: accessed-variable=PRP_SR_WSParTimerGEEDCM.WSParTimerGEEDCM
              dra_WSParTimerPrecElec: accessed-variable=PRP_SR_WSParTimerPrecElec.WSParTimerPrecElec
              dra_WSParTimerPrecond: accessed-variable=PRP_SR_WSParTimerPrecond.WSParTimerPrecond
              dra_WSParTimerPrecTherm: accessed-variable=PRP_SR_WSParTimerPrecTherm.WSParTimerPrecTherm
              dra_WSParTimerRTAB: accessed-variable=PRP_SR_WSParTimerRTAB.WSParTimerRTAB
          data-write-access:
            23 x access:
              dwa_Annee: accessed-variable=PRP_SR_Annee.Annee
              dwa_AnneePourAff: accessed-variable=PRP_SR_AnneePourAff.AnneePourAff
              dwa_CptTempVehicule: accessed-variable=PRP_SR_CptTempVehicule.CptTempVehicule
              dwa_Heure: accessed-variable=PRP_SR_Heure.Heure
              dwa_HeureCAN: accessed-variable=PRP_SR_HeureCAN.HeureCAN
              dwa_Jour: accessed-variable=PRP_SR_Jour.Jour
              dwa_Minute: accessed-variable=PRP_SR_Minute.Minute
              dwa_MinuteCAN: accessed-variable=PRP_SR_MinuteCAN.MinuteCAN
              dwa_Mois: accessed-variable=PRP_SR_Mois.Mois
              dwa_SEC_Affichage: accessed-variable=PRP_SR_SEC_Affichage.SEC_Affichage
              dwa_SEC_EtatProgRevGEEAQEB: accessed-variable=PRP_SR_SEC_EtatProgRevGEEAQEB.SEC_EtatProgRevGEEAQEB
              dwa_SEC_EtatProgRevGEEDCM: accessed-variable=PRP_SR_SEC_EtatProgRevGEEDCM.SEC_EtatProgRevGEEDCM
              dwa_SEC_EtatProgRevPrecondElec: accessed-variable=PRP_SR_SEC_EtatProgRevPrecondElec.SEC_EtatProgRevPrecondElec
              dwa_SEC_EtatProgRevPrecondTherm: accessed-variable=PRP_SR_SEC_EtatProgRevPrecondTherm.SEC_EtatProgRevPrecondTherm
              dwa_SEC_EtatProgRevRTAB: accessed-variable=PRP_SR_SEC_EtatProgRevRTAB.SEC_EtatProgRevRTAB
              dwa_SEC_HProgRevPrecondTherm: accessed-variable=PRP_SR_SEC_HProgRevPrecondTherm.SEC_HProgRevPrecondTherm
              dwa_SEC_TypeAffichageHorloge: accessed-variable=PRP_SR_SEC_TypeAffichageHorloge.SEC_TypeAffichageHorloge
              dwa_WSParTimerGEEAQEB: accessed-variable=PRP_SR_WSParTimerGEEAQEB.WSParTimerGEEAQEB
              dwa_WSParTimerGEEDCM: accessed-variable=PRP_SR_WSParTimerGEEDCM.WSParTimerGEEDCM
              dwa_WSParTimerPrecElec: accessed-variable=PRP_SR_WSParTimerPrecElec.WSParTimerPrecElec
              dwa_WSParTimerPrecond: accessed-variable=PRP_SR_WSParTimerPrecond.WSParTimerPrecond
              dwa_WSParTimerPrecTherm: accessed-variable=PRP_SR_WSParTimerPrecTherm.WSParTimerPrecTherm
              dwa_WSParTimerRTAB: accessed-variable=PRP_SR_WSParTimerRTAB.WSParTimerRTAB
          read-local-variables:
            7 x access:
              rlv_IRVA27_DbrtBATT: accessed-variable=IRVA27_DbrtBATT
              rlv_IRVA27_DeProg_AbsAlarm_All: accessed-variable=IRVA27_DeProg_AbsAlarm_All
              rlv_IRVA27_DeProg_RelAlarm_All: accessed-variable=IRVA27_DeProg_RelAlarm_All
              rlv_IRVA27_OldTimeEnMinute: accessed-variable=IRVA27_OldTimeEnMinute
              rlv_IRVA27_ReveilBSI: accessed-variable=IRVA27_ReveilBSI
              rlv_IRVA27_SAV_OldCptTempVehicule: accessed-variable=IRVA27_SAV_OldCptTempVehicule
              rlv_IRVA27_SEC_TchgtBSIDbrtBATT: accessed-variable=IRVA27_SEC_TchgtBSIDbrtBATT
          4 x sync call, all with timeout=0:
            sscp_RUNI_A27_CS_TS_Counter_Cnt_Get: operation=RP_CS_TS_Counter.Cnt_Get
            sscp_RUNI_A27_CS_TS_DateTime_Date_Get: operation=RP_CS_TS_DateTime.Date_Get
            sscp_RUNI_A27_CS_TS_DateTime_Date_Set: operation=RP_CS_TS_DateTime.Date_Set
            sscp_RUNI_A27_CS_TS_DateTime_Time_Get: operation=RP_CS_TS_DateTime.Time_Get
          written-local-variables:
            7 x access:
              wlv_IRVA27_DbrtBATT: accessed-variable=IRVA27_DbrtBATT
              wlv_IRVA27_DeProg_AbsAlarm_All: accessed-variable=IRVA27_DeProg_AbsAlarm_All
              wlv_IRVA27_DeProg_RelAlarm_All: accessed-variable=IRVA27_DeProg_RelAlarm_All
              wlv_IRVA27_OldTimeEnMinute: accessed-variable=IRVA27_OldTimeEnMinute
              wlv_IRVA27_ReveilBSI: accessed-variable=IRVA27_ReveilBSI
              wlv_IRVA27_SAV_OldCptTempVehicule: accessed-variable=IRVA27_SAV_OldCptTempVehicule
              wlv_IRVA27_SEC_TchgtBSIDbrtBATT: accessed-variable=IRVA27_SEC_TchgtBSIDbrtBATT
        RUNS_ProgReveilAbs_Release
          data-read-access:
            8 x access:
              dra_Annee: accessed-variable=PRP_SR_Annee.Annee
              dra_Heure: accessed-variable=PRP_SR_Heure.Heure
              dra_Jour: accessed-variable=PRP_SR_Jour.Jour
              dra_Minute: accessed-variable=PRP_SR_Minute.Minute
              dra_Mois: accessed-variable=PRP_SR_Mois.Mois
              dra_SEC_Affichage: accessed-variable=PRP_SR_SEC_Affichage.SEC_Affichage
              dra_SEC_EtatProgRevPrecond: accessed-variable=PRP_SR_SEC_EtatProgRevPrecond.SEC_EtatProgRevPrecond
              dra_SEC_EtatProgRevPrecondTherm: accessed-variable=PRP_SR_SEC_EtatProgRevPrecondTherm.SEC_EtatProgRevPrecondTherm
          data-write-access:
            access dwa_SEC_EtatProgRevPrecond: accessed-variable=PRP_SR_SEC_EtatProgRevPrecond.SEC_EtatProgRevPrecond
            access dwa_SEC_EtatProgRevPrecondTherm: accessed-variable=PRP_SR_SEC_EtatProgRevPrecondTherm.SEC_EtatProgRevPrecondTherm
          read-local-variables:
            access rlv_IRVA27_DeProg_AbsAlarm_PreCond: accessed-variable=IRVA27_DeProg_AbsAlarm_PreCond
            access rlv_IRVA27_DeProg_AbsAlarm_PT: accessed-variable=IRVA27_DeProg_AbsAlarm_PT
          written-local-variables:
            access wlv_IRVA27_DeProg_AbsAlarm_PreCond: accessed-variable=IRVA27_DeProg_AbsAlarm_PreCond
            access wlv_IRVA27_DeProg_AbsAlarm_PT: accessed-variable=IRVA27_DeProg_AbsAlarm_PT
        RUNS_ProgReveilAbs_Request
          data-read-access:
            9 x access:
              dra_Annee: accessed-variable=PRP_SR_Annee.Annee
              dra_Heure: accessed-variable=PRP_SR_Heure.Heure
              dra_Jour: accessed-variable=PRP_SR_Jour.Jour
              dra_Minute: accessed-variable=PRP_SR_Minute.Minute
              dra_Mois: accessed-variable=PRP_SR_Mois.Mois
              dra_SEC_Affichage: accessed-variable=PRP_SR_SEC_Affichage.SEC_Affichage
              dra_SEC_EtatProgRevPrecond: accessed-variable=PRP_SR_SEC_EtatProgRevPrecond.SEC_EtatProgRevPrecond
              dra_SEC_EtatProgRevPrecondTherm: accessed-variable=PRP_SR_SEC_EtatProgRevPrecondTherm.SEC_EtatProgRevPrecondTherm
              dra_SEC_HProgRevPrecondTherm: accessed-variable=PRP_SR_SEC_HProgRevPrecondTherm.SEC_HProgRevPrecondTherm
          data-write-access:
            access dwa_SEC_EtatProgRevPrecond: accessed-variable=PRP_SR_SEC_EtatProgRevPrecond.SEC_EtatProgRevPrecond
            access dwa_SEC_EtatProgRevPrecondTherm: accessed-variable=PRP_SR_SEC_EtatProgRevPrecondTherm.SEC_EtatProgRevPrecondTherm
            access dwa_SEC_HProgRevPrecondTherm: accessed-variable=PRP_SR_SEC_HProgRevPrecondTherm.SEC_HProgRevPrecondTherm
          read-local-variables:
            access rlv_IRVA27_DeProg_AbsAlarm_PreCond: accessed-variable=IRVA27_DeProg_AbsAlarm_PreCond
            access rlv_IRVA27_DeProg_AbsAlarm_PT: accessed-variable=IRVA27_DeProg_AbsAlarm_PT
          sync call sscp_RUNS_ProgReveilAbs_Request_CS_TS_AbsoluteAlarm_AbsAlarm_Set: operation=RP_CS_TS_AbsoluteAlarm.AbsAlarm_Set, timeout=0
          written-local-variables:
            access wlv_IRVA27_DeProg_AbsAlarm_PreCond: accessed-variable=IRVA27_DeProg_AbsAlarm_PreCond
            access wlv_IRVA27_DeProg_AbsAlarm_PT: accessed-variable=IRVA27_DeProg_AbsAlarm_PT
        RUNS_ProgReveilRel_Release
          data-read-access:
            12 x access:
              dra_Annee: accessed-variable=PRP_SR_Annee.Annee
              dra_CptTempVehicule: accessed-variable=PRP_SR_CptTempVehicule.CptTempVehicule
              dra_Heure: accessed-variable=PRP_SR_Heure.Heure
              dra_Jour: accessed-variable=PRP_SR_Jour.Jour
              dra_Minute: accessed-variable=PRP_SR_Minute.Minute
              dra_Mois: accessed-variable=PRP_SR_Mois.Mois
              dra_SEC_Affichage: accessed-variable=PRP_SR_SEC_Affichage.SEC_Affichage
              dra_SEC_EtatProgRevGEEAQEB: accessed-variable=PRP_SR_SEC_EtatProgRevGEEAQEB.SEC_EtatProgRevGEEAQEB
              dra_SEC_EtatProgRevGEEDCM: accessed-variable=PRP_SR_SEC_EtatProgRevGEEDCM.SEC_EtatProgRevGEEDCM
              dra_SEC_EtatProgRevPrecond: accessed-variable=PRP_SR_SEC_EtatProgRevPrecond.SEC_EtatProgRevPrecond
              dra_SEC_EtatProgRevPrecondElec: accessed-variable=PRP_SR_SEC_EtatProgRevPrecondElec.SEC_EtatProgRevPrecondElec
              dra_SEC_EtatProgRevRTAB: accessed-variable=PRP_SR_SEC_EtatProgRevRTAB.SEC_EtatProgRevRTAB
          data-write-access:
            5 x access:
              dwa_SEC_EtatProgRevGEEAQEB: accessed-variable=PRP_SR_SEC_EtatProgRevGEEAQEB.SEC_EtatProgRevGEEAQEB
              dwa_SEC_EtatProgRevGEEDCM: accessed-variable=PRP_SR_SEC_EtatProgRevGEEDCM.SEC_EtatProgRevGEEDCM
              dwa_SEC_EtatProgRevPrecond: accessed-variable=PRP_SR_SEC_EtatProgRevPrecond.SEC_EtatProgRevPrecond
              dwa_SEC_EtatProgRevPrecondElec: accessed-variable=PRP_SR_SEC_EtatProgRevPrecondElec.SEC_EtatProgRevPrecondElec
              dwa_SEC_EtatProgRevRTAB: accessed-variable=PRP_SR_SEC_EtatProgRevRTAB.SEC_EtatProgRevRTAB
          read-local-variables:
            6 x access:
              rlv_IRVA27_DeProg_RelAlarm_All: accessed-variable=IRVA27_DeProg_RelAlarm_All
              rlv_IRVA27_DeProg_RelAlarm_AQEB: accessed-variable=IRVA27_DeProg_RelAlarm_AQEB
              rlv_IRVA27_DeProg_RelAlarm_DCM: accessed-variable=IRVA27_DeProg_RelAlarm_DCM
              rlv_IRVA27_DeProg_RelAlarm_PE: accessed-variable=IRVA27_DeProg_RelAlarm_PE
              rlv_IRVA27_DeProg_RelAlarm_PreCond: accessed-variable=IRVA27_DeProg_RelAlarm_PreCond
              rlv_IRVA27_DeProg_RelAlarm_RTAB: accessed-variable=IRVA27_DeProg_RelAlarm_RTAB
          written-local-variables:
            6 x access:
              wlv_IRVA27_DeProg_RelAlarm_All: accessed-variable=IRVA27_DeProg_RelAlarm_All
              wlv_IRVA27_DeProg_RelAlarm_AQEB: accessed-variable=IRVA27_DeProg_RelAlarm_AQEB
              wlv_IRVA27_DeProg_RelAlarm_DCM: accessed-variable=IRVA27_DeProg_RelAlarm_DCM
              wlv_IRVA27_DeProg_RelAlarm_PE: accessed-variable=IRVA27_DeProg_RelAlarm_PE
              wlv_IRVA27_DeProg_RelAlarm_PreCond: accessed-variable=IRVA27_DeProg_RelAlarm_PreCond
              wlv_IRVA27_DeProg_RelAlarm_RTAB: accessed-variable=IRVA27_DeProg_RelAlarm_RTAB
        RUNS_ProgReveilRel_Request
          data-read-access:
            12 x access:
              dra_Annee: accessed-variable=PRP_SR_Annee.Annee
              dra_CptTempVehicule: accessed-variable=PRP_SR_CptTempVehicule.CptTempVehicule
              dra_Heure: accessed-variable=PRP_SR_Heure.Heure
              dra_Jour: accessed-variable=PRP_SR_Jour.Jour
              dra_Minute: accessed-variable=PRP_SR_Minute.Minute
              dra_Mois: accessed-variable=PRP_SR_Mois.Mois
              dra_SEC_Affichage: accessed-variable=PRP_SR_SEC_Affichage.SEC_Affichage
              dra_SEC_EtatProgRevGEEAQEB: accessed-variable=PRP_SR_SEC_EtatProgRevGEEAQEB.SEC_EtatProgRevGEEAQEB
              dra_SEC_EtatProgRevGEEDCM: accessed-variable=PRP_SR_SEC_EtatProgRevGEEDCM.SEC_EtatProgRevGEEDCM
              dra_SEC_EtatProgRevPrecond: accessed-variable=PRP_SR_SEC_EtatProgRevPrecond.SEC_EtatProgRevPrecond
              dra_SEC_EtatProgRevPrecondElec: accessed-variable=PRP_SR_SEC_EtatProgRevPrecondElec.SEC_EtatProgRevPrecondElec
              dra_SEC_EtatProgRevRTAB: accessed-variable=PRP_SR_SEC_EtatProgRevRTAB.SEC_EtatProgRevRTAB
          data-write-access:
            5 x access:
              dwa_SEC_EtatProgRevGEEAQEB: accessed-variable=PRP_SR_SEC_EtatProgRevGEEAQEB.SEC_EtatProgRevGEEAQEB
              dwa_SEC_EtatProgRevGEEDCM: accessed-variable=PRP_SR_SEC_EtatProgRevGEEDCM.SEC_EtatProgRevGEEDCM
              dwa_SEC_EtatProgRevPrecond: accessed-variable=PRP_SR_SEC_EtatProgRevPrecond.SEC_EtatProgRevPrecond
              dwa_SEC_EtatProgRevPrecondElec: accessed-variable=PRP_SR_SEC_EtatProgRevPrecondElec.SEC_EtatProgRevPrecondElec
              dwa_SEC_EtatProgRevRTAB: accessed-variable=PRP_SR_SEC_EtatProgRevRTAB.SEC_EtatProgRevRTAB
          read-local-variables:
            11 x access:
              rlv_IRVA27_DeProg_RelAlarm_All: accessed-variable=IRVA27_DeProg_RelAlarm_All
              rlv_IRVA27_DeProg_RelAlarm_AQEB: accessed-variable=IRVA27_DeProg_RelAlarm_AQEB
              rlv_IRVA27_DeProg_RelAlarm_DCM: accessed-variable=IRVA27_DeProg_RelAlarm_DCM
              rlv_IRVA27_DeProg_RelAlarm_PE: accessed-variable=IRVA27_DeProg_RelAlarm_PE
              rlv_IRVA27_DeProg_RelAlarm_PreCond: accessed-variable=IRVA27_DeProg_RelAlarm_PreCond
              rlv_IRVA27_DeProg_RelAlarm_RTAB: accessed-variable=IRVA27_DeProg_RelAlarm_RTAB
              rlv_IRVA27_SEC_TProgReveilGEEAQEB: accessed-variable=IRVA27_SEC_TProgReveilGEEAQEB
              rlv_IRVA27_SEC_TProgReveilGEEDCM: accessed-variable=IRVA27_SEC_TProgReveilGEEDCM
              rlv_IRVA27_SEC_TProgReveilPE: accessed-variable=IRVA27_SEC_TProgReveilPE
              rlv_IRVA27_SEC_TProgReveilPreCond: accessed-variable=IRVA27_SEC_TProgReveilPreCond
              rlv_IRVA27_SEC_TProgReveilRTAB: accessed-variable=IRVA27_SEC_TProgReveilRTAB
          sync call sscp_RUNS_ProgReveilRel_Request_CS_TS_RelativeAlarm_RelAlarm_Set: operation=RP_CS_TS_RelativeAlarm.RelAlarm_Set, timeout=0
          written-local-variables:
            11 x access:
              wlv_IRVA27_DeProg_RelAlarm_All: accessed-variable=IRVA27_DeProg_RelAlarm_All
              wlv_IRVA27_DeProg_RelAlarm_AQEB: accessed-variable=IRVA27_DeProg_RelAlarm_AQEB
              wlv_IRVA27_DeProg_RelAlarm_DCM: accessed-variable=IRVA27_DeProg_RelAlarm_DCM
              wlv_IRVA27_DeProg_RelAlarm_PE: accessed-variable=IRVA27_DeProg_RelAlarm_PE
              wlv_IRVA27_DeProg_RelAlarm_PreCond: accessed-variable=IRVA27_DeProg_RelAlarm_PreCond
              wlv_IRVA27_DeProg_RelAlarm_RTAB: accessed-variable=IRVA27_DeProg_RelAlarm_RTAB
              wlv_IRVA27_SEC_TProgReveilGEEAQEB: accessed-variable=IRVA27_SEC_TProgReveilGEEAQEB
              wlv_IRVA27_SEC_TProgReveilGEEDCM: accessed-variable=IRVA27_SEC_TProgReveilGEEDCM
              wlv_IRVA27_SEC_TProgReveilPE: accessed-variable=IRVA27_SEC_TProgReveilPE
              wlv_IRVA27_SEC_TProgReveilPreCond: accessed-variable=IRVA27_SEC_TProgReveilPreCond
              wlv_IRVA27_SEC_TProgReveilRTAB: accessed-variable=IRVA27_SEC_TProgReveilRTAB
        RUNPI_ASWC_A27
package /RootP_Implementatation
  swc implementation Implementatation_ASWC_A27: programming-language=C, sw-version=1.0.0, vendor-id=1, behavior=IB_ASWC_A27
    code-descriptors:
      code SRC: artifact-descriptors=autosar-engineering-object={short-label=EngObject, category=SWSRC}
    resource consumption Resources
